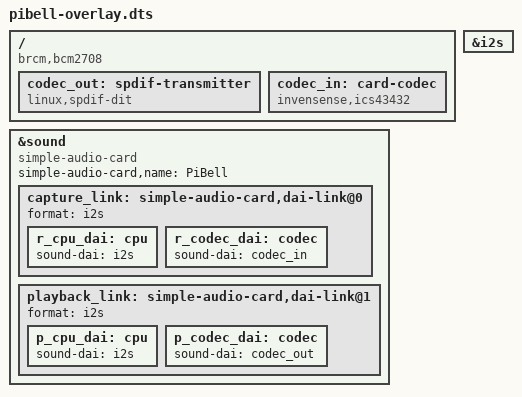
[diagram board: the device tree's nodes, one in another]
/dts-v1/;
/plugin/;

/ {
    compatible = "brcm,bcm2708";

    fragment@0 {
        target-path = "/";
        __overlay__ {
            codec_out: spdif-transmitter {
                #address-cells = <0>;
                #size-cells = <0>;
                #sound-dai-cells = <0>;
                compatible = "linux,spdif-dit";
                status = "okay";
            };

            codec_in: card-codec {
                #sound-dai-cells = <0>;
                compatible = "invensense,ics43432";
                status = "okay";
            };
        };
    };

    fragment@1 {
        target = <&i2s>;
        __overlay__ {
            #sound-dai-cells = <0>;
            status = "okay";
        };
    };

    fragment@2 {
        target = <&sound>;
        snd: __overlay__ {
            compatible = "simple-audio-card";
            simple-audio-card,name = "PiBell";

            status="okay";

            capture_link: simple-audio-card,dai-link@0 {
                format = "i2s";

                r_cpu_dai: cpu {
                    sound-dai = <&i2s>;

/* example TDM slot configuration
                    dai-tdm-slot-num = <2>;
                    dai-tdm-slot-width = <32>;
*/
                };

                r_codec_dai: codec {
                    sound-dai = <&codec_in>;
                };
            };

            playback_link: simple-audio-card,dai-link@1 {
                format = "i2s";

                p_cpu_dai: cpu {
                    sound-dai = <&i2s>;

/* example TDM slot configuration
                    dai-tdm-slot-num = <2>;
                    dai-tdm-slot-width = <32>;
*/
                };

                p_codec_dai: codec {
                    sound-dai = <&codec_out>;
                };
            };
        };
    };

    __overrides__ {
        alsaname = <&snd>, "simple-audio-card,name";
    };
};
